AUTOSAR XML (schema 00051)
standard types defined: boolean, uint16, uint32, uint8
package /Components
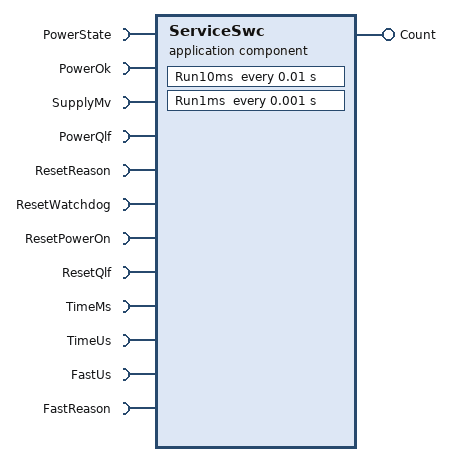
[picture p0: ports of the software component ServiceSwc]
  application sw component type ServiceSwc
    12 x require port:
      PowerState: nonqueued-receiver-com-spec{data-element=PowerState, init-value=0}, required-interface=PowerState
      PowerOk: nonqueued-receiver-com-spec{data-element=PowerOk, init-value=0}, required-interface=PowerOk
      SupplyMv: nonqueued-receiver-com-spec{data-element=SupplyMv, init-value=0}, required-interface=SupplyMv
      PowerQlf: nonqueued-receiver-com-spec{data-element=PowerQlf, init-value=0}, required-interface=PowerQlf
      ResetReason: nonqueued-receiver-com-spec{data-element=ResetReason, init-value=0}, required-interface=ResetReason
      ResetWatchdog: nonqueued-receiver-com-spec{data-element=ResetWatchdog, init-value=0}, required-interface=ResetWatchdog
      ResetPowerOn: nonqueued-receiver-com-spec{data-element=ResetPowerOn, init-value=0}, required-interface=ResetPowerOn
      ResetQlf: nonqueued-receiver-com-spec{data-element=ResetQlf, init-value=0}, required-interface=ResetQlf
      TimeMs: nonqueued-receiver-com-spec{data-element=TimeMs, init-value=0}, required-interface=TimeMs
      TimeUs: nonqueued-receiver-com-spec{data-element=TimeUs, init-value=0}, required-interface=TimeUs
      FastUs: nonqueued-receiver-com-spec{data-element=FastUs, init-value=0}, required-interface=FastUs
      FastReason: nonqueued-receiver-com-spec{data-element=FastReason, init-value=0}, required-interface=FastReason
    provide port Count: nonqueued-sender-com-spec{data-element=Count, init-value=0}, provided-interface=Count
    behavior ServiceSwc_IB
      timing event Event_Run10ms: start-on-event=Run10ms, period=0.01
      timing event Event_Run1ms: start-on-event=Run1ms, period=0.001
      runnable Run10ms: symbol=ServiceSwc_Run10ms
        data-receive-point-by-arguments:
          10 x access:
            IN_PowerState_PowerState: accessed-variable=PowerState.PowerState
            IN_PowerOk_PowerOk: accessed-variable=PowerOk.PowerOk
            IN_SupplyMv_SupplyMv: accessed-variable=SupplyMv.SupplyMv
            IN_PowerQlf_PowerQlf: accessed-variable=PowerQlf.PowerQlf
            IN_ResetReason_ResetReason: accessed-variable=ResetReason.ResetReason
            IN_ResetWatchdog_ResetWatchdog: accessed-variable=ResetWatchdog.ResetWatchdog
            IN_ResetPowerOn_ResetPowerOn: accessed-variable=ResetPowerOn.ResetPowerOn
            IN_ResetQlf_ResetQlf: accessed-variable=ResetQlf.ResetQlf
            IN_TimeMs_TimeMs: accessed-variable=TimeMs.TimeMs
            IN_TimeUs_TimeUs: accessed-variable=TimeUs.TimeUs
        data-send-points:
          access OUT_Count_Count: accessed-variable=Count.Count
      runnable Run1ms: symbol=ServiceSwc_Run1ms
        data-receive-point-by-arguments:
          access IN_FastUs_FastUs: accessed-variable=FastUs.FastUs
          access IN_FastReason_FastReason: accessed-variable=FastReason.FastReason
package /Interfaces
  13 x sender receiver interface:
    PowerState
      data PowerState: type=uint8
    PowerOk
      data PowerOk: type=boolean
    SupplyMv
      data SupplyMv: type=uint16
    PowerQlf
      data PowerQlf: type=uint8
    ResetReason
      data ResetReason: type=uint16
    ResetWatchdog
      data ResetWatchdog: type=boolean
    ResetPowerOn
      data ResetPowerOn: type=boolean
    ResetQlf
      data ResetQlf: type=uint32
    TimeMs
      data TimeMs: type=uint32
    TimeUs
      data TimeUs: type=uint32
    FastUs
      data FastUs: type=uint32
    FastReason
      data FastReason: type=uint8
    Count
      data Count: type=uint32
